# STM32WL33 register map
File version: 1.0
CPU: CM0+ r0p0, little endian, MPU, no FPU, 4 interrupt priority bits
Registers are 32-bit, read-write, reset 0x0 unless marked. A register's access mark holds for its fields unless they carry their own. Offsets are from the block's base; [hi:lo] are bit positions.

## DAC — DAC address block description
Base 0x40006000
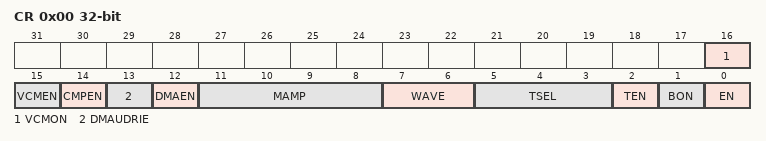
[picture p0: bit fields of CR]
0x00 CR (reset mask 0xFFFF)
  [16] VCMON — VCMON: VCMBUFF power-up. This bit is set and cleared by software. 0: VCM BUFFER OFF 1: VCM BUFFER ON
  [15] VCMEN — VCMEN: DAC channel output to VCM BUFFER enable. This bit is set and cleared by software. 0: DAC channel output to VCM BUFFER disabled 1: DAC channel output to VCM BUFFER enabled
  [14] CMPEN — CMPEN: DAC channel output to COMP INMINUS enable. This bit is set and cleared by software. 0: DAC channel output to COMP INMINUS disabled 1: DAC channel output to COMP INMINUS enabled
  [13] DMAUDRIE — DMAUDRIE: DAC channel DMA Underrun Interrupt enable This bit is set and cleared by software. 0: DAC channel DMA Underrun Interrupt disabled 1: DAC channel DMA Underrun Interrupt enabled
  [12] DMAEN — DMAEN: DAC channel DMA enable This bit is set and cleared by software. 0: DAC channel DMA mode disabled 1: DAC channel DMA mode enabled
  [11:8] MAMP — MAMP[3:0]: DAC channel mask amplitude selector These bits are written by software to select mask in wave generation mode or amplitude in triangle generation mode. 0000: Unmask bit0 of LFSR triangle amplitude equal to 1 0001: Unmask bits[1:0] of LFSR triangle amplitude equal to 3 0010: Unmask bits[2:0] of LFSR triangle amplitude equal to 7 0011: Unmask bits[3:0] of LFSR triangle amplitude equal to 15 0100: Unmask bits[4:0] of LFSR triangle amplitude equal to 31 greater than or equal to 0101: Unmask bits[5:0] of LFSR triangle amplitude equal to 63
  [7:6] WAVE — WAVE[1:0]: DAC channel noise/triangle wave generation enable These bits are set and cleared by software. 00: wave generation disabled 01: Noise wave generation enabled 1x: Triangle wave generation enabled Note: Only used if bit TEN = 1 (DAC channel trigger enabled).
  [5:3] TSEL — TSEL[2:0]: DAC channel trigger selection These bits select the external event used to trigger DAC channel. 000: Timer 16 TRGO event 001: PA8 pin event from SYSCFG 010 to 011: Reserved 111: Software trigger Only used if bit TEN = 1 (DAC channel trigger enabled).
  [2] TEN — TEN: DAC channel trigger enable This bit is set and cleared by software to enable/disable DAC channel trigger. 0: DAC channel trigger disabled and data written into the DAC_DHR register are transferred one APB0 clock cycle later to the DAC_DOR register 1: DAC channel trigger enabled and data from the DAC_DHR register are transferred three APB0 clock cycles later to the DAC_DOR register Note: When software trigger is selected, the transfer from the DAC_DHR register to the DAC_DOR register takes only one APB0 clock cycle.
  [1] BON — BON: DAC channel output buffer enable. This bit is set and cleared by software to enable/disable DAC channel output buffer. 0: DAC channel output buffer disabled 1: DAC channel output buffer enabled
  [0] EN — EN: DAC channel enable This bit is set and cleared by software to enable/disable DAC channel. 0: DAC channel disabled 1: DAC channel enabled
0x04 SWTRIGR
  [0] SWTRIG wo — SWTRIG: DAC channel software trigger This bit is set by software to enable/disable the software trigger. 0: Software trigger disabled 1: Software trigger enabled Note: This bit is cleared by hardware (one APB0 clock cycle later) once the DAC_DHR register value has been loaded into the DAC_DOR register.
0x10 DHR
  [5:0] DACDHR — DACDHR[5:0]: DAC channel 6-bit data These bits are written by software which specifies 6-bit data for DAC channel.
0x2C DOR ro (reset mask 0xF)
  [5:0] DACDOR — DACDOR[5:0]: DAC channel data output These bits are read-only, they contain data output for DAC channel.
0x34 SR (reset mask 0xF)
  [13] DMAUDR — DMAUDR: DAC channel DMA underrun flag This bit is set by hardware and cleared by software (by writing it to 1). 0: No DMA underrun error condition occurred for DAC channel 1: DMA underrun error condition occurred for DAC channel (the currently selected trigger is driving DAC channel conversion at a frequency higher than the DMA service capability rate)
